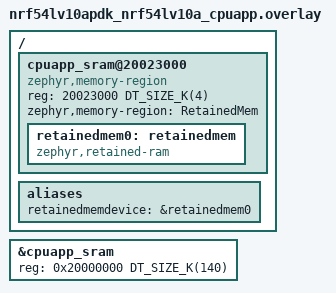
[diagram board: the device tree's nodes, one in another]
/ {
	cpuapp_sram@20023000 {
		compatible = "zephyr,memory-region", "mmio-sram";
		reg = <20023000 DT_SIZE_K(4)>;
		zephyr,memory-region = "RetainedMem";
		status = "okay";

		retainedmem0: retainedmem {
			compatible = "zephyr,retained-ram";
			status = "okay";
		};
	};

	aliases {
		retainedmemdevice = &retainedmem0;
	};
};

&cpuapp_sram {
	/* Shrink SRAM size to avoid overlap with retained memory region:
	 * 144 - 4 = 140 = 0x23000
	 */
	reg = <0x20000000 DT_SIZE_K(140)>;
	ranges = <0x0 0x20000000 0x23000>;
};
